# ATSAME51J18A register map
Vendor: Microchip Technology; Series: SAME51; File version: 0
CPU: CM4 r0p1, selectable endian, MPU, FPU, 3 interrupt priority bits
Registers are 32-bit, read-write, reset 0x0 unless marked. A register's access mark holds for its fields unless they carry their own. Offsets are from the block's base; [hi:lo] are bit positions; {n}, {i} and the like mark numbered series; 'fields as' and 'values as' point back to an identical list.

## NVMCTRL — Non-Volatile Memory Controller
Base 0x41004000; register names take the prefix NVMCTRL_
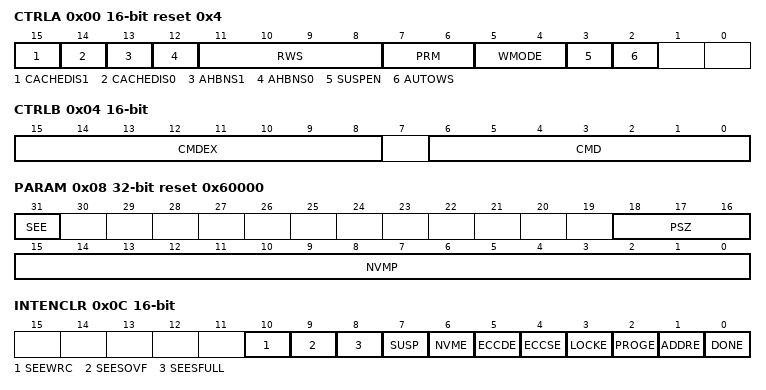
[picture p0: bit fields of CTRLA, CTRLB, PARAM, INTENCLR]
0x00 CTRLA 16-bit reset 0x4 — Control A
  [15] CACHEDIS1 — AHB1 Cache Disable
  [14] CACHEDIS0 — AHB0 Cache Disable
  [13] AHBNS1 — Force AHB1 access to NONSEQ, burst transfers are continuously rearbitrated
  [12] AHBNS0 — Force AHB0 access to NONSEQ, burst transfers are continuously rearbitrated
  [11:8] RWS — NVM Read Wait States
  [7:6] PRM — Power Reduction Mode during Sleep
    0=SEMIAUTO (NVM block enters low-power mode when entering standby mode. NVM block enters low-power mode when SPRM command is issued. NVM block exits low-power mode upon first access.); 1=FULLAUTO (NVM block enters low-power mode when entering standby mode. NVM block enters low-power mode when SPRM command is issued. NVM block exits low-power mode when system is not in standby mode.); 3=MANUAL (NVM block does not enter low-power mode when entering standby mode. NVM block enters low-power mode when SPRM command is issued. NVM block exits low-power mode upon first access.)
  [5:4] WMODE — Write Mode
    0=MAN (Manual Write); 1=ADW (Automatic Double Word Write); 2=AQW (Automatic Quad Word); 3=AP (Automatic Page Write)
  [3] SUSPEN — Suspend Enable
  [2] AUTOWS — Auto Wait State Enable
0x04 CTRLB 16-bit wo — Control B
  [15:8] CMDEX — Command Execution
    165=KEY (Execution Key)
  [6:0] CMD — Command
    0=EP (Erase Page - Only supported in the USER and AUX pages.); 1=EB (Erase Block - Erases the block addressed by the ADDR register, not supported in the user page); 3=WP (Write Page - Writes the contents of the page buffer to the page addressed by the ADDR register, not supported in the user page); 4=WQW (Write Quad Word - Writes a 128-bit word at the location addressed by the ADDR register.); 16=SWRST (Software Reset - Power-Cycle the NVM memory and replay the device automatic calibration procedure and resets the module configuration registers); 17=LR (Lock Region - Locks the region containing the address location in the ADDR register.); 18=UR (Unlock Region - Unlocks the region containing the address location in the ADDR register.); 19=SPRM (Sets the power reduction mode.); 20=CPRM (Clears the power reduction mode.); 21=PBC (Page Buffer Clear - Clears the page buffer.); 22=SSB (Set Security Bit); 23=BKSWRST (Bank swap and system reset, if SMEE is used also reallocate SMEE data into the opposite BANK); 24=CELCK (Chip Erase Lock - DSU.CE command is not available); 25=CEULCK (Chip Erase Unlock - DSU.CE command is available); 26=SBPDIS (Sets STATUS.BPDIS, Boot loader protection is discarded until CBPDIS is issued or next start-up sequence); 27=CBPDIS (Clears STATUS.BPDIS, Boot loader protection is not discarded); 48=ASEES0 (Activate SmartEEPROM Sector 0, deactivate Sector 1); 49=ASEES1 (Activate SmartEEPROM Sector 1, deactivate Sector 0); 50=SEERALOC (Starts SmartEEPROM sector reallocation algorithm); 51=SEEFLUSH (Flush SMEE data when in buffered mode); 52=LSEE (Lock access to SmartEEPROM data from any mean); 53=USEE (Unlock access to SmartEEPROM data); 54=LSEER (Lock access to the SmartEEPROM Register Address Space (above 64KB)); 55=USEER (Unlock access to the SmartEEPROM Register Address Space (above 64KB))
0x08 PARAM ro reset 0x60000 — NVM Parameter
  [31] SEE — SmartEEPROM Supported
    10=A (163840 bytes); 9=147456 bytes; 8=131072 bytes; 7=114688 bytes; 6=98304 bytes; 5=81920 bytes; 4=65536 bytes; 3=49152 bytes; 2=32768 bytes; 1=16384 bytes; 0=0 bytes
  [18:16] PSZ — Page Size
    0=8 bytes; 1=16 bytes; 2=32 bytes; 3=64 bytes; 4=128 bytes; 5=256 bytes; 6=512 bytes; 7=1024 bytes
  [15:0] NVMP — NVM Pages
0x0C INTENCLR 16-bit — Interrupt Enable Clear
  [10] SEEWRC — SEE Write Completed Interrupt Clear
  [9] SEESOVF — Active SEES Overflow Interrupt Clear
  [8] SEESFULL — Active SEES Full Interrupt Clear
  [7] SUSP — Suspended Write Or Erase Interrupt Clear
  [6] NVME — NVM Error Interrupt Clear
  [5] ECCDE — ECC Dual Error Interrupt Clear
  [4] ECCSE — ECC Single Error Interrupt Clear
  [3] LOCKE — Lock Error Interrupt Clear
  [2] PROGE — Programming Error Interrupt Clear
  [1] ADDRE — Address Error
  [0] DONE — Command Done Interrupt Clear
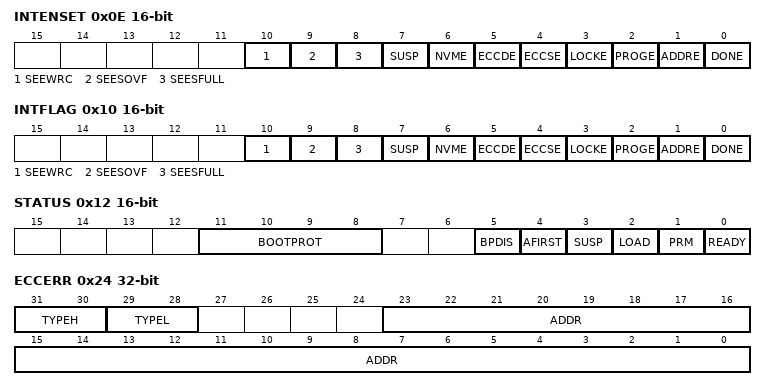
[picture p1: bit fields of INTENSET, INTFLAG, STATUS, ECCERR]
0x0E INTENSET 16-bit — Interrupt Enable Set
  [10] SEEWRC — SEE Write Completed Interrupt Enable
  [9] SEESOVF — Active SEES Overflow Interrupt Enable
  [8] SEESFULL — Active SEES Full Interrupt Enable
  [7] SUSP — Suspended Write Or Erase Interrupt Enable
  [6] NVME — NVM Error Interrupt Enable
  [5] ECCDE — ECC Dual Error Interrupt Enable
  [4] ECCSE — ECC Single Error Interrupt Enable
  [3] LOCKE — Lock Error Interrupt Enable
  [2] PROGE — Programming Error Interrupt Enable
  [1] ADDRE — Address Error Interrupt Enable
  [0] DONE — Command Done Interrupt Enable
0x10 INTFLAG 16-bit — Interrupt Flag Status and Clear
  [10] SEEWRC — SEE Write Completed
  [9] SEESOVF write-1-clears — Active SEES Overflow
  [8] SEESFULL write-1-clears — Active SEES Full
  [7] SUSP write-1-clears — Suspended Write Or Erase Operation
  [6] NVME write-1-clears — NVM Error
  [5] ECCDE ro — ECC Dual Error
  [4] ECCSE ro — ECC Single Error
  [3] LOCKE write-1-clears — Lock Error
  [2] PROGE write-1-clears — Programming Error
  [1] ADDRE write-1-clears — Address Error
  [0] DONE write-1-clears — Command Done
0x12 STATUS 16-bit ro
  [11:8] BOOTPROT — Boot Loader Protection Size
    15=0 kbytes; 14=8 kbytes; 13=16 kbytes; 12=24 kbytes; 11=32 kbytes; 10=40 kbytes; 9=48 kbytes; 8=56 kbytes; 7=64 kbytes; 6=72 kbytes; 5=80 kbytes; 4=88 kbytes; 3=96 kbytes; 2=104 kbytes; 1=112 kbytes; 0=120 kbytes
  [5] BPDIS — Boot Loader Protection Disable
  [4] AFIRST — BANKA First
  [3] SUSP — NVM Write Or Erase Operation Is Suspended
  [2] LOAD — NVM Page Buffer Active Loading
  [1] PRM — Power Reduction Mode
  [0] READY — Ready to accept a command
0x14 ADDR — Address
  [23:0] ADDR — NVM Address
0x18 RUNLOCK ro — Lock Section
  [31:0] RUNLOCK — Region Un-Lock Bits
{0x1C+4i} PBLDATA[{i}] (i=0..1) ro reset 0xFFFFFFFF — Page Buffer Load Data x
  [31:0] DATA — Page Buffer Data
0x24 ECCERR ro — ECC Error Status Register
  [31:30] TYPEH — High Double-Word Error Type
    0=None (No Error Detected Since Last Read); 1=Single (At Least One Single Error Detected Since last Read); 2=Dual (At Least One Dual Error Detected Since Last Read)
  [29:28] TYPEL — Low Double-Word Error Type
    values as TYPEH
  [23:0] ADDR — Error Address
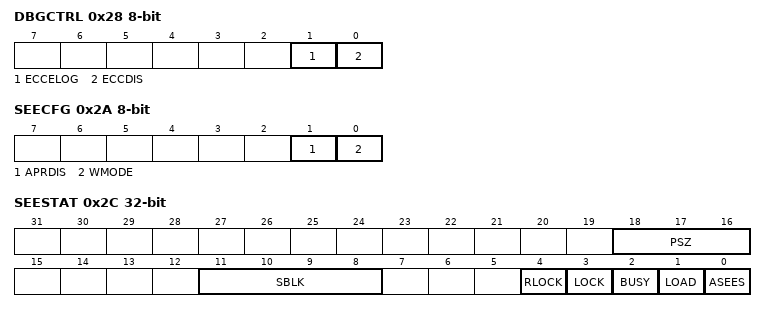
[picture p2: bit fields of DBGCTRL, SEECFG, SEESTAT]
0x28 DBGCTRL 8-bit — Debug Control
  [1] ECCELOG — Debugger ECC Error Tracking Mode
  [0] ECCDIS — Debugger ECC Read Disable
0x2A SEECFG 8-bit — SmartEEPROM Configuration Register
  [1] APRDIS — Automatic Page Reallocation Disable
  [0] WMODE — Write Mode
    0=UNBUFFERED (A NVM write command is issued after each write in the pagebuffer); 1=BUFFERED (A NVM write command is issued when a write to a new page is requested)
0x2C SEESTAT ro — SmartEEPROM Status Register
  [18:16] PSZ — SmartEEPROM Page Size
  [11:8] SBLK — Blocks Number In a Sector
  [4] RLOCK — SmartEEPROM Write Access To Register Address Space Is Locked
  [3] LOCK — SmartEEPROM Write Access Is Locked
  [2] BUSY
  [1] LOAD — Page Buffer Loaded
  [0] ASEES — Active SmartEEPROM Sector
